AUTOSAR XML (schema 4-2-1)
package /ComponentTypes
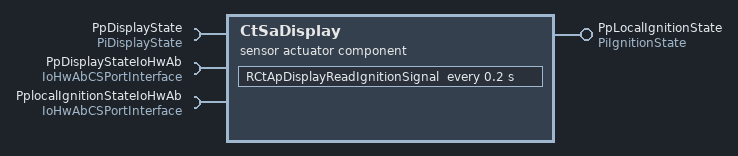
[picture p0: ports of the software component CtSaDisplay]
  sensor actuator sw component type CtSaDisplay
    provide port PpLocalIgnitionState: nonqueued-sender-com-spec{data-element=DeIgnitionState, init-value=0}, provided-interface=PiIgnitionState
    require port PpDisplayState: required-interface=PiDisplayState
      required-com-specs:
        data-element=DeDisplayBusState, filter=data-filter-type=ALWAYS, init-value=constant-reference=CBackLightDimCtrlInit
        data-element=DeLightOnOffCounter, filter=data-filter-type=ALWAYS, init-value=constant-reference=CUInt32Zero
        data-element=DeOdometerValue, filter=data-filter-type=ALWAYS, init-value=constant-reference=CUInt32Zero
        data-element=DeOdometerWriteRequestPending, filter=data-filter-type=ALWAYS, init-value=constant-reference=CWriteReqNotPending
    require port PpDisplayStateIoHwAb: required-interface=IoHwAbCSPortInterface
    require port PplocalIgnitionStateIoHwAb: required-interface=IoHwAbCSPortInterface
    behavior CtSaDisplay_InternalBehavior: data-type-mapping=DemoTypeMapping
      4 x data received event:
        DRT_RCtApDisplayBusStateHandling_PpDisplayState_DeDisplayBusState: start-on-event=RCtApDisplayBusStateHandling, data=PpDisplayState.DeDisplayBusState
        DRT_RCtApDisplayLightOnOffHandling_PpDisplayState_DeLightOnOffCounter: start-on-event=RCtApDisplayLightOnOffHandling, data=PpDisplayState.DeLightOnOffCounter
        DRT_RCtApDisplayOdometerValue_PpDisplayState_DeOdometerValue: start-on-event=RCtApDisplayOdometerValue, data=PpDisplayState.DeOdometerValue
        DRT_RCtApDisplayOdometerWriteRequestPending_PpDisplayState_DeOdometerWriteRequrestPending: start-on-event=RCtApDisplayOdometerWriteRequestPending, data=PpDisplayState.DeOdometerWriteRequestPending
      timing event TMT_RCtApDisplayReadIgnitionSignal: start-on-event=RCtApDisplayReadIgnitionSignal, period=0.2
      5 x runnable:
        RCtApDisplayBusStateHandling
          data-receive-point-by-arguments:
            access REC_PpDisplayState_DeDisplayBusState: accessed-variable=PpDisplayState.DeDisplayBusState
          sync call SC_PpDisplayStateIoHwAb_WriteChannel: operation=PpDisplayStateIoHwAb.WriteChannel, timeout=0
          sync call SC_PplocalIgnitionStateIoHwAb_ReadChannel: operation=PplocalIgnitionStateIoHwAb.ReadChannel, timeout=0
        RCtApDisplayLightOnOffHandling
          data-receive-point-by-arguments:
            access REC_PpDisplayState_DeLightOnOffCounter: accessed-variable=PpDisplayState.DeLightOnOffCounter
        RCtApDisplayOdometerValue
          data-receive-point-by-arguments:
            access REC_PpDisplayState_DeOdometerValue: accessed-variable=PpDisplayState.DeOdometerValue
        RCtApDisplayOdometerWriteRequestPending
          data-receive-point-by-arguments:
            access REC_PpDisplayState_DeOdometerWriteRequestPending: accessed-variable=PpDisplayState.DeOdometerWriteRequestPending
        RCtApDisplayReadIgnitionSignal
          data-send-points:
            access SEND_PpLocalIgnitionState_DeIgnitionState: accessed-variable=PpLocalIgnitionState.DeIgnitionState
          sync call SC_PplocalIgnitionStateIoHwAb_ReadChannel: operation=PplocalIgnitionStateIoHwAb.ReadChannel, timeout=0
  swc implementation CtSaDisplay_Implementation: behavior=CtSaDisplay_InternalBehavior
    code-descriptors:
      code Default: artifact-descriptors=autosar-engineering-object={short-label=Default, category=SWSRC}
